# S1C31W74 register map
Vendor: Epson; Series: S1C31W74; File version: 1.11
CPU: CM0PLUS r0p1, little endian, MPU, no FPU, VTOR, 2 interrupt priority bits
Registers are 16-bit, read-write, reset 0x0 unless marked. A register's access mark holds for its fields unless they carry their own. Offsets are from the block's base; [hi:lo] are bit positions; 'fields as' and 'values as' point back to an identical list.

## CLG — Clock sources control and clock supply management
Base 0x40000040
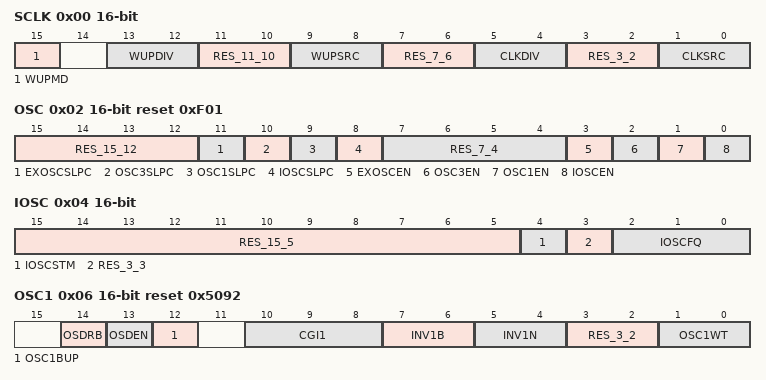
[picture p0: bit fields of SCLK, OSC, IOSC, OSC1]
0x00 SCLK — System Clock Control Register
  [15] WUPMD — Wakeup mode select (can be write protected)
    0=SAME_SRC (Same source); 1=SEL_SRC (Selected source)
  [13:12] WUPDIV — Wakeup system clock division ratio select (can be write protected)
  [11:10] RES_11_10 ro — Reserved bits
  [9:8] WUPSRC — Wakeup system clock source select (can be write protected)
    0=IOSC; 1=OSC1; 2=OSC3; 3=EXOSC
  [7:6] RES_7_6 ro — Reserved bits
  [5:4] CLKDIV — System clock division ratio select (can be write protected)
  [3:2] RES_3_2 ro — Reserved bits
  [1:0] CLKSRC — System clock source select (can be write protected)
    0=IOSC; 1=OSC1; 2=OSC3; 3=EXOSC
0x02 OSC reset 0xF01 — Oscillation Control Register
  [15:12] RES_15_12 ro — Reserved bits
  [11] EXOSCSLPC — EXOSC clock sleep control (can be write protected)
    0=DISABLE; 1=ENABLE
  [10] OSC3SLPC — OSC3 clock sleep control
    0=DISABLE; 1=ENABLE
  [9] OSC1SLPC — OSC1 clock sleep control
    0=DISABLE; 1=ENABLE
  [8] IOSCSLPC — IOSC clock sleep control
    0=DISABLE; 1=ENABLE
  [7:4] RES_7_4 ro — Reserved bits
  [3] EXOSCEN — EXOSC enable
    0=DISABLE; 1=ENABLE
  [2] OSC3EN — OSC3 enable
    0=DISABLE; 1=ENABLE
  [1] OSC1EN — OSC1 enable
    0=DISABLE; 1=ENABLE
  [0] IOSCEN — IOSC enable
    0=DISABLE; 1=ENABLE
0x04 IOSC — IOSC Control Register
  [15:5] RES_15_5 ro — Reserved bits
  [4] IOSCSTM — IOSC self trimming enable (can be write protected)
    on write: 0=TRIM_STOP (Stop trimming); 1=TRIM_START (Start trimming) | on read: 0=STOPPED (Trimming has finished); 1=RUNNING (Trimming is executing)
  [3] RES_3_3 ro — Reserved bits
  [2:0] IOSCFQ — IOSC frequency select (can be write protected)
    0=1MHZ; 1=2MHZ; 2=1MHZ; 3=2MHZ; 4=8MHZ; 5=12MHZ; 6=16MHZ; 7=20MHZ
0x06 OSC1 reset 0x5092 — OSC1 Control Register
  [14] OSDRB — OSC stop reboot enable (can be write protected)
    0=DISABLE; 1=ENABLE
  [13] OSDEN — OSC stop detector enable (can be write protected)
    0=DISABLE; 1=ENABLE
  [12] OSC1BUP — OSC boost-up boot enable (can be write protected)
    0=DISABLE; 1=ENABLE
  [10:8] CGI1 — Gate capacitance select (can be write protected)
    0=0PF (0pF+(5pF)); 1=2PF (2pF+(5pF)); 2=4PF (4pF+(5pF)); 3=6PF (6pF+(5pF)); 4=8PF (8pF+(5pF)); 5=10PF (10pF+(5pF)); 6=12PF (12pF+(5pF)); 7=14PF (14pF+(5pF))
  [7:6] INV1B — Boot OSC inverter select (can be write protected)
  [5:4] INV1N — Normal OSC inverter select (can be write protected)
  [3:2] RES_3_2 ro — Reserved bits
  [1:0] OSC1WT — OSC1 wait cycle select (can be write protected)
    0=1_CLK (1 clock (reserved)); 1=4096_CLK (4096 clocks); 2=16384_CLK (16384 clocks); 3=65536_CLK (65536 clocks)
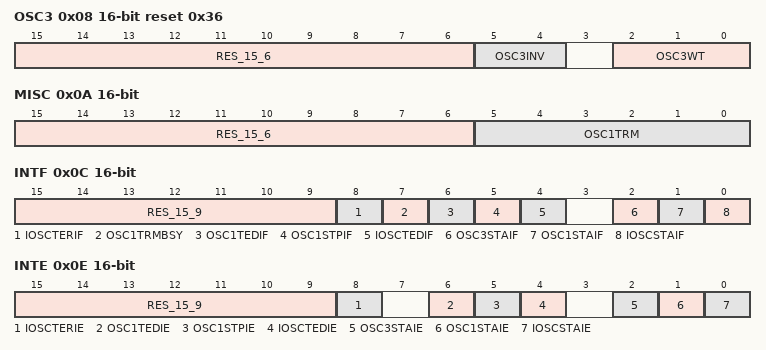
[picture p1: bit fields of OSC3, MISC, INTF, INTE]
0x08 OSC3 reset 0x36 — OSC3 Control Register
  [15:6] RES_15_6 ro — Reserved bits
  [5:4] OSC3INV — OSC3 X'tal mode inverter select (can be write protected)
  [2:0] OSC3WT — OSC3 wait cycle select (can be write protected)
    0=4_CLK (4 clocks); 1=16_CLK (16 clocks); 2=64_CLK (64 clocks); 3=256_CLK (256 clocks); 4=1024_CLK (1024 clocks); 5=4096_CLK (4096 clocks); 6=16384_CLK (16384 clocks); 7=65536_CLK (65536 clocks)
0x0A MISC — MISC Control Register
  [15:6] RES_15_6 ro — Reserved bits
  [5:0] OSC1TRM wo — OSC1 theoretical regulation trimming value (in 2's complement)
0x0C INTF — Interrupt Flag Register
  [15:9] RES_15_9 ro — Reserved bits
  [8] IOSCTERIF ro write-1-clears — IOSC trimming error interrupt flag
    0=NOT_OCCURED (No cause of interrupt occurred); 1=OCCURED (Cause of interrupt occurred)
  [7] OSC1TRMBSY ro — OSC1 theoretical regulation busy status
    0=NOT_BUSY (OSC1 oscillation auto-trimming NOT in progress, read/write to OSC1 theoretical regulation trimming value is possible.); 1=BUSY (OSC1 oscillation auto-trimming in progress)
  [6] OSC1TEDIF ro write-1-clears — OSC1 theoretical regulation end interrupt flag
    values as IOSCTERIF
  [5] OSC1STPIF ro write-1-clears — OSC1 oscillation stop interrupt flag
    values as IOSCTERIF
  [4] IOSCTEDIF ro write-1-clears — IOSC trimming end interrupt flag
    values as IOSCTERIF
  [2] OSC3STAIF ro write-1-clears — OSC3 oscillation stable interrupt flag
    values as IOSCTERIF
  [1] OSC1STAIF ro write-1-clears — OSC1 oscillation stable interrupt flag
    values as IOSCTERIF
  [0] IOSCSTAIF ro write-1-clears — IOSC oscillation stable interrupt flag
    values as IOSCTERIF
0x0E INTE — Interrupt Enable Register
  [15:9] RES_15_9 ro — Reserved bits
  [8] IOSCTERIE — IOSC trimming error interrupt enable
    0=DISABLE; 1=ENABLE
  [6] OSC1TEDIE — OSC1 theoretical regulation end interrupt enable
    0=DISABLE; 1=ENABLE
  [5] OSC1STPIE — OSC1 oscillation stop interrupt enable
    0=DISABLE; 1=ENABLE
  [4] IOSCTEDIE — IOSC trimming end interrupt enable
    0=DISABLE; 1=ENABLE
  [2] OSC3STAIE — OSC3 oscillation stable interrupt enable
    0=DISABLE; 1=ENABLE
  [1] OSC1STAIE — OSC1 oscillation stable interrupt enable
    0=DISABLE; 1=ENABLE
  [0] IOSCSTAIE — IOSC oscillation stable interrupt enable
    0=DISABLE; 1=ENABLE
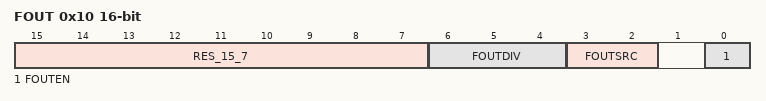
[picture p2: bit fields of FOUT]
0x10 FOUT — FOUT Control Register
  [15:7] RES_15_7 ro — Reserved bits
  [6:4] FOUTDIV — FOUT clock division ratio select
  [3:2] FOUTSRC — FOUTA clock source select
    0=IOSC; 1=OSC1; 2=OSC3; 3=SYSCLK (SYSTEM CLK)
  [0] FOUTEN — FOUTA output enable
    0=DISABLE; 1=ENABLE
